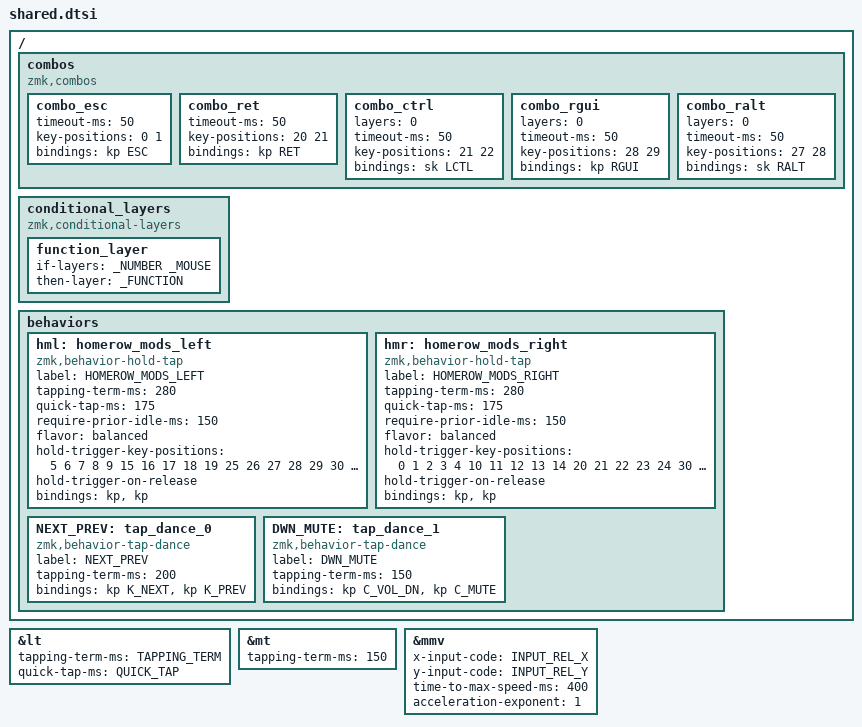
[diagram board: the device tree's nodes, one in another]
/*
 * Shared ZMK configuration for multiple keyboards
 * Copyright (c) 2020 The ZMK Contributors
 * SPDX-License-Identifier: MIT
 */

#define ZMK_POINTING_DEFAULT_MOVE_VAL 4500
#define ZMK_POINTING_DEFAULT_SCRL_VAL 20

#define TAPPING_TERM 150
#define QUICK_TAP 200

/* LAYERS */
#define _QWERTY 0
#define _NAVI 1
#define _SYMBOL 2
#define _NUMBER 3
#define _MOUSE 4
#define _FUNCTION 5

&lt {
    tapping-term-ms = <TAPPING_TERM>;
    quick-tap-ms = <QUICK_TAP>;
};

&mt {
  tapping-term-ms = <150>;
};

&mmv {
  x-input-code = <INPUT_REL_X>;
  y-input-code = <INPUT_REL_Y>;
  time-to-max-speed-ms = <400>;
  acceleration-exponent = <1>;
};

/ {
  combos {
    compatible = "zmk,combos";

    combo_esc {
      timeout-ms = <50>;
      key-positions = <0 1>;
      bindings = <&kp ESC>;
    };
    combo_ret {
      timeout-ms = <50>;
      key-positions = <20 21>;
      bindings = <&kp RET>;
    };

    // Mod combos
    combo_ctrl {
      layers = <0>;
      timeout-ms = <50>;
      // X + C
      key-positions = <21 22>;
      bindings = <&sk LCTL>;
    };
    combo_rgui {
      layers = <0>;
      timeout-ms = <50>;
      // . + /
      key-positions = <28 29>;
      bindings = <&kp RGUI>;
    };
    combo_ralt {
      layers = <0>;
      timeout-ms = <50>;
      // , + .
      key-positions = <27 28>;
      bindings = <&sk RALT>;
    };
  };

  conditional_layers {
    compatible = "zmk,conditional-layers";

    function_layer {
      if-layers = <_NUMBER _MOUSE>;
      then-layer = <_FUNCTION>;
    };
  };

  behaviors {
    hml: homerow_mods_left {
      compatible = "zmk,behavior-hold-tap";
      label = "HOMEROW_MODS_LEFT";
      #binding-cells = <2>;
      tapping-term-ms = <280>;
      quick-tap-ms = <175>;
      require-prior-idle-ms = <150>;
      flavor = "balanced";
      hold-trigger-key-positions = <5 6 7 8 9 15 16 17 18 19 25 26 27 28 29 30 31 32 33 34 35>;
      hold-trigger-on-release;
      bindings = <&kp>, <&kp>;
    };
    hmr: homerow_mods_right {
      compatible = "zmk,behavior-hold-tap";
      label = "HOMEROW_MODS_RIGHT";
      #binding-cells = <2>;
      tapping-term-ms = <280>;
      quick-tap-ms = <175>;
      require-prior-idle-ms = <150>;
      flavor = "balanced";
      hold-trigger-key-positions = <0 1 2 3 4 10 11 12 13 14 20 21 22 23 24 30 31 32 33 34 35>;
      hold-trigger-on-release;
      bindings = <&kp>, <&kp>;
    };
    NEXT_PREV: tap_dance_0 {
      compatible = "zmk,behavior-tap-dance";
      label = "NEXT_PREV";
      #binding-cells = <0>;
      tapping-term-ms = <200>;
      bindings = <&kp K_NEXT>, <&kp K_PREV>;
    };
    DWN_MUTE: tap_dance_1 {
      compatible = "zmk,behavior-tap-dance";
      label = "DWN_MUTE";
      #binding-cells = <0>;
      tapping-term-ms = <150>;
      bindings = <&kp C_VOL_DN>, <&kp C_MUTE>;
    };
  };
};

/* SHARED LAYER DEFINITIONS */
#define QWERTY_LAYER \
  &kp Q           &kp W           &kp E           &kp R            &kp T              &kp Y         &kp U         &kp I         &kp O         &kp P \
  &hml LGUI A     &hml LALT S     &hml LCTRL D    &hml LSHIFT F    &kp G              &kp H         &hmr LSHIFT J  &hmr LCTRL K   &hmr LALT L    &hmr LGUI SEMI \
  &kp Z           &kp X           &kp C           &kp V            &kp B              &kp N         &kp M         &kp COMMA     &kp DOT       &kp FSLH

#define NAVI_LAYER \
  &sk RGUI        &sk RALT        &sk RCTRL       &sk RSHFT        &none              &caps_word    &kp LC(X)     &kp LC(C)     &kp LC(V)     &kp LC(Z) \
  &sk LGUI        &sk LALT        &sk LCTRL       &sk LSHFT        &none              &kp LEFT      &kp DOWN      &kp UP        &kp RIGHT     &kp TAB \
  &none           &none           &none           &none            &kp INS            &kp HOME      &kp PG_DN     &kp PG_UP     &kp END       &kp DEL

#define SYMBOL_LAYER \
  &kp LBRC        &kp AMPS        &kp STAR        &kp PIPE         &kp RBRC           &none         &kp SQT       &kp DQT       &none         &kp GRAVE \
  &kp LPAR        &kp DLLR        &kp PRCNT       &kp CARET        &kp RPAR           &kp TILDE     &kp MINUS     &kp PLUS      &kp EQUAL     &kp QMARK \
  &kp LBKT        &kp EXCL        &kp AT          &kp HASH         &kp RBKT           &none         &kp UNDER     &kp SEMI      &kp COLON     &kp BSLH

#define NUMBER_LAYER \
  &none           &none           &none           &none            &none              &kp STAR      &kp N7        &kp N8        &kp N9        &kp FSLH \
  &sk LGUI        &sk LALT        &sk LCTRL       &sk LSHFT        &none              &kp MINUS     &kp N4        &kp N5        &kp N6        &kp N0 \
  &none           &none           &none           &none            &none              &kp PLUS      &kp N1        &kp N2        &kp N3        &kp DOT

#define MOUSE_LAYER \
  &msc SCRL_LEFT  &msc SCRL_UP    &mmv MOVE_UP    &msc SCRL_DOWN   &msc SCRL_RIGHT    &trans        &trans        &trans        &kp LGUI      &kp LALT \
  &trans          &mmv MOVE_LEFT  &mmv MOVE_DOWN  &mmv MOVE_RIGHT  &trans             &trans        &mkp MB1      &mkp MB2      &mkp MB3      &kp LCTRL \
  &trans          &trans          &trans          &trans           &trans             &trans        &trans        &trans        &trans        &kp LSHFT

#define FUNCTION_LAYER \
  &kp F12         &kp F7          &kp F8          &kp F9          &kp PAUSE_BREAK     &NEXT_PREV    &DWN_MUTE     &kp C_PP      &kp C_VOL_UP  &none \
  &kp F11         &kp F4          &kp F5          &kp F6          &kp PSCRN           &none         &kp LSHFT     &kp LCTRL     &kp LALT      &kp LGUI \
  &kp F10         &kp F1          &kp F2          &kp F3          &kp SLCK            &bt BT_SEL 0  &bt BT_SEL 1  &bt BT_SEL 2  &bt BT_SEL 3  &bt BT_CLR
